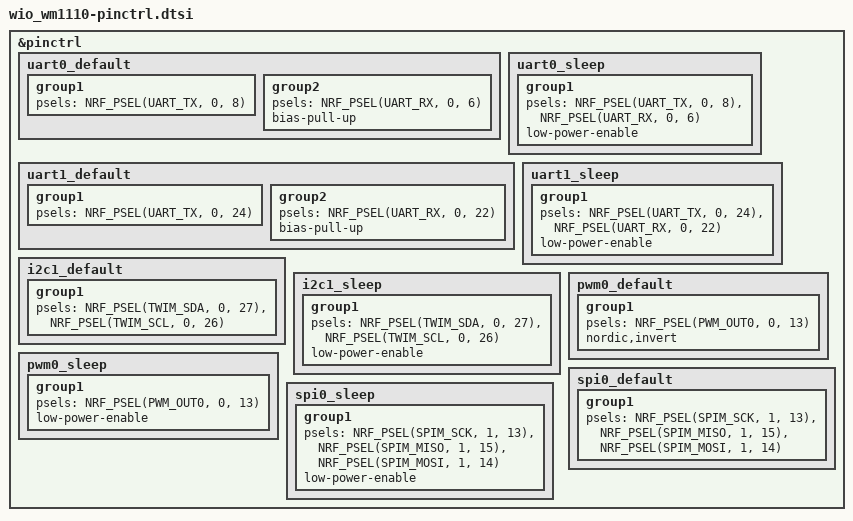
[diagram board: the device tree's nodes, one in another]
/*
 * Copyright (c) 2022 Nordic Semiconductor
 * SPDX-License-Identifier: Apache-2.0
 */

&pinctrl {
	uart0_default: uart0_default {
		group1 {
			psels = <NRF_PSEL(UART_TX, 0, 8)>;
		};
		group2 {
			psels = <NRF_PSEL(UART_RX, 0, 6)>;
		bias-pull-up;
		};
	};

	uart0_sleep: uart0_sleep {
		group1 {
			psels = <NRF_PSEL(UART_TX, 0, 8)>,
			<NRF_PSEL(UART_RX, 0, 6)>;
		low-power-enable;
		};
	};

	uart1_default: uart1_default {
		group1 {
			psels = <NRF_PSEL(UART_TX, 0, 24)>;
		};
		group2 {
			psels = <NRF_PSEL(UART_RX, 0, 22)>;
		bias-pull-up;
		};
	};

	uart1_sleep: uart1_sleep {
		group1 {
			psels = <NRF_PSEL(UART_TX, 0, 24)>,
			<NRF_PSEL(UART_RX, 0, 22)>;
		low-power-enable;
		};
	};

	i2c1_default: i2c1_default {
		group1 {
			psels = <NRF_PSEL(TWIM_SDA, 0, 27)>,
				<NRF_PSEL(TWIM_SCL, 0, 26)>;
		};
	};

	i2c1_sleep: i2c1_sleep {
		group1 {
			psels = <NRF_PSEL(TWIM_SDA, 0, 27)>,
				<NRF_PSEL(TWIM_SCL, 0, 26)>;
			low-power-enable;
		};
	};
	
	pwm0_default: pwm0_default {
		group1 {
			psels = <NRF_PSEL(PWM_OUT0, 0, 13)>;
			nordic,invert;
		};
	};

	pwm0_sleep: pwm0_sleep {
		group1 {
			psels = <NRF_PSEL(PWM_OUT0, 0, 13)>;
			low-power-enable;
		};
	};

	spi0_default: spi0_default {
		group1 {
			psels = <NRF_PSEL(SPIM_SCK, 1, 13)>,
					<NRF_PSEL(SPIM_MISO, 1, 15)>,
					<NRF_PSEL(SPIM_MOSI, 1, 14)>;
		};
	};

	spi0_sleep: spi0_sleep {
		group1 {
			psels = <NRF_PSEL(SPIM_SCK, 1, 13)>,
					<NRF_PSEL(SPIM_MISO, 1, 15)>,
					<NRF_PSEL(SPIM_MOSI, 1, 14)>;
			low-power-enable;
		};
	};

};
